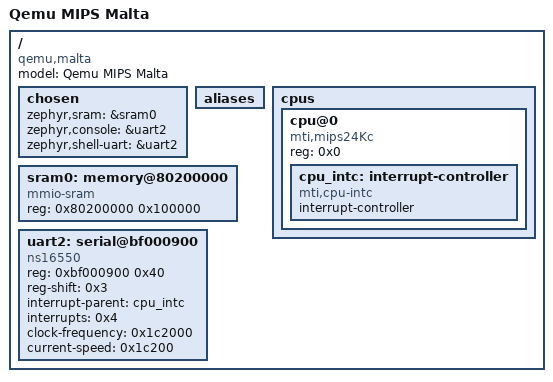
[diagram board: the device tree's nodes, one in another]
/dts-v1/;

/* node '/' defined in zephyr/dts/common/skeleton.dtsi:9 */
/ {
	#address-cells = < 0x1 >;  /* in zephyr/dts/common/skeleton.dtsi:10 */
	#size-cells = < 0x1 >;     /* in zephyr/dts/common/skeleton.dtsi:11 */
	model = "Qemu MIPS Malta"; /* in zephyr/boards/qemu/malta/qemu_malta.dts:12 */
	compatible = "qemu,malta"; /* in zephyr/boards/qemu/malta/qemu_malta.dts:13 */

	/* node '/chosen' defined in zephyr/dts/common/skeleton.dtsi:13 */
	chosen {
		zephyr,sram = &sram0;       /* in zephyr/boards/qemu/malta/qemu_malta.dts:16 */
		zephyr,console = &uart2;    /* in zephyr/boards/qemu/malta/qemu_malta.dts:17 */
		zephyr,shell-uart = &uart2; /* in zephyr/boards/qemu/malta/qemu_malta.dts:18 */
	};

	/* node '/aliases' defined in zephyr/dts/common/skeleton.dtsi:15 */
	aliases {
	};

	/* node '/cpus' defined in zephyr/boards/qemu/malta/qemu_malta.dts:21 */
	cpus {
		#address-cells = < 0x1 >; /* in zephyr/boards/qemu/malta/qemu_malta.dts:22 */
		#size-cells = < 0x0 >;    /* in zephyr/boards/qemu/malta/qemu_malta.dts:23 */

		/* node '/cpus/cpu@0' defined in zephyr/boards/qemu/malta/qemu_malta.dts:25 */
		cpu@0 {
			device_type = "cpu";         /* in zephyr/boards/qemu/malta/qemu_malta.dts:26 */
			compatible = "mti,mips24Kc"; /* in zephyr/boards/qemu/malta/qemu_malta.dts:27 */
			reg = < 0x0 >;               /* in zephyr/boards/qemu/malta/qemu_malta.dts:28 */

			/* node '/cpus/cpu@0/interrupt-controller' defined in zephyr/boards/qemu/malta/qemu_malta.dts:30 */
			cpu_intc: interrupt-controller {
				#interrupt-cells = < 0x1 >;  /* in zephyr/boards/qemu/malta/qemu_malta.dts:31 */
				compatible = "mti,cpu-intc"; /* in zephyr/boards/qemu/malta/qemu_malta.dts:32 */
				interrupt-controller;        /* in zephyr/boards/qemu/malta/qemu_malta.dts:33 */
				phandle = < 0x1 >;           /* in zephyr/boards/qemu/malta/qemu_malta.dts:48 */
			};
		};
	};

	/* node '/memory@80200000' defined in zephyr/boards/qemu/malta/qemu_malta.dts:38 */
	sram0: memory@80200000 {
		device_type = "memory";        /* in zephyr/boards/qemu/malta/qemu_malta.dts:39 */
		compatible = "mmio-sram";      /* in zephyr/boards/qemu/malta/qemu_malta.dts:40 */
		reg = < 0x80200000 0x100000 >; /* in zephyr/boards/qemu/malta/qemu_malta.dts:41 */
	};

	/* node '/serial@bf000900' defined in zephyr/boards/qemu/malta/qemu_malta.dts:44 */
	uart2: serial@bf000900 {
		compatible = "ns16550";           /* in zephyr/boards/qemu/malta/qemu_malta.dts:45 */
		reg = < 0xbf000900 0x40 >;        /* in zephyr/boards/qemu/malta/qemu_malta.dts:46 */
		reg-shift = < 0x3 >;              /* in zephyr/boards/qemu/malta/qemu_malta.dts:47 */
		interrupt-parent = < &cpu_intc >; /* in zephyr/boards/qemu/malta/qemu_malta.dts:48 */
		interrupts = < 0x4 >;             /* in zephyr/boards/qemu/malta/qemu_malta.dts:49 */
		clock-frequency = < 0x1c2000 >;   /* in zephyr/boards/qemu/malta/qemu_malta.dts:51 */
		current-speed = < 0x1c200 >;      /* in zephyr/boards/qemu/malta/qemu_malta.dts:52 */
		status = "okay";                  /* in zephyr/boards/qemu/malta/qemu_malta.dts:53 */
	};
};
